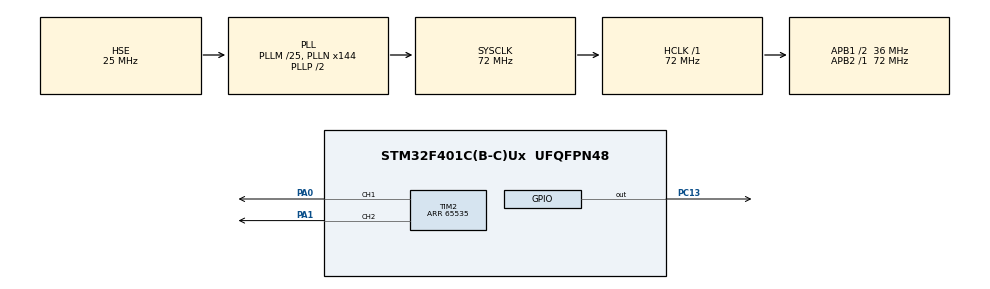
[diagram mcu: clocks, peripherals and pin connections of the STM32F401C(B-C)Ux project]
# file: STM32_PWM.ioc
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Mcu.Family=STM32F4
Mcu.Name=STM32F401C(B-C)Ux
Mcu.Package=UFQFPN48
NVIC.PriorityGroup=NVIC_PRIORITYGROUP_4
PA0-WKUP.Signal=S_TIM2_CH1_ETR
PA1.Signal=S_TIM2_CH2
PC13-ANTI_TAMP.Signal=GPIO_Output
PH0\ -\ OSC_IN.Mode=HSE-External-Oscillator
PH0\ -\ OSC_IN.Signal=RCC_OSC_IN
PH1\ -\ OSC_OUT.Mode=HSE-External-Oscillator
PH1\ -\ OSC_OUT.Signal=RCC_OSC_OUT
ProjectManager.HeapSize=0x200
ProjectManager.StackSize=0x400
ProjectManager.TargetToolchain=STM32CubeIDE
RCC.48MHZClocksFreq_Value=36000000
RCC.AHBFreq_Value=72000000
RCC.APB1CLKDivider=RCC_HCLK_DIV2
RCC.APB1Freq_Value=36000000
RCC.APB1TimFreq_Value=72000000
RCC.APB2Freq_Value=72000000
RCC.APB2TimFreq_Value=72000000
RCC.CortexFreq_Value=72000000
RCC.HCLKFreq_Value=72000000
RCC.HSE_VALUE=25000000
RCC.HSI_VALUE=16000000
RCC.LSE_VALUE=32768
RCC.PLLM=25
RCC.PLLN=144
RCC.PLLSourceVirtual=RCC_PLLSOURCE_HSE
RCC.SYSCLKFreq_VALUE=72000000
RCC.SYSCLKSource=RCC_SYSCLKSOURCE_PLLCLK
RCC.VCOOutputFreq_Value=144000000
SH.S_TIM2_CH1_ETR.0=TIM2_CH1,PWM Generation1 CH1
SH.S_TIM2_CH2.0=TIM2_CH2,PWM Generation2 CH2
TIM2.AutoReloadPreload=TIM_AUTORELOAD_PRELOAD_ENABLE
TIM2.Channel-PWM\ Generation1\ CH1=TIM_CHANNEL_1
TIM2.Channel-PWM\ Generation2\ CH2=TIM_CHANNEL_2
TIM2.Period=65535
VP_TIM2_VS_ClockSourceINT.Mode=Internal
board=custom

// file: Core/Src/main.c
/* USER CODE BEGIN Header */
/**
  ******************************************************************************
  * @file           : main.c
  * @brief          : Main program body
  ******************************************************************************
  * @attention
  *
  * Copyright (c) 2021 STMicroelectronics.
  * All rights reserved.
  *
  * This software is licensed under terms that can be found in the LICENSE file
  * in the root directory of this software component.
  * If no LICENSE file comes with this software, it is provided AS-IS.
  *
  ******************************************************************************
  */
/* USER CODE END Header */
#include "main.h"
#include "tim.h"
#include "gpio.h"

void SystemClock_Config(void);

int main(void)
{
  /* USER CODE BEGIN 1 */
	int32_t pwm_resolution = 65535;
	int32_t cycles = 500;
	int32_t pwm_increment = pwm_resolution/cycles;
	int32_t current_pwm = 0;
	int32_t cycle_duration = 2; // In milliseconds
	int32_t direction = 1;
	int32_t current_cycle = 0;
	int32_t pin_select = 1;
  /* USER CODE END 1 */

  /* MCU Configuration--------------------------------------------------------*/

  /* Reset of all peripherals, Initializes the Flash interface and the Systick. */
  HAL_Init();

  /* Configure the system clock */
  SystemClock_Config();

  /* Initialize all configured peripherals */
  MX_GPIO_Init();
  MX_TIM2_Init();
  /* USER CODE BEGIN 2 */
	GPIOC -> ODR |= GPIO_PIN_13;
  /* USER CODE END 2 */

  /* Infinite loop */
  /* USER CODE BEGIN WHILE */
  HAL_TIM_PWM_Start(&htim2, TIM_CHANNEL_1);
  HAL_TIM_PWM_Start(&htim2, TIM_CHANNEL_2);
  int32_t timer = HAL_GetTick();
	while (1)
	{
		if ((HAL_GetTick() - timer) > cycle_duration)
		{
			current_pwm += pwm_increment * direction;
			if (pin_select == 1)
				TIM2->CCR1 = current_pwm;
			else
				TIM2->CCR2 = current_pwm;

			current_cycle += direction;
			if (current_cycle >= cycles)
				direction *= -1; // reached half a cycle, flip direction
			else if (current_cycle <= 0)
			{
				direction *= -1; // reached end of a cycle, flip direction and pin
				pin_select *= -1;
				HAL_Delay(250);
			}

			timer = HAL_GetTick();
		}
	}
    /* USER CODE END WHILE */

}

void SystemClock_Config(void)
{
  RCC_OscInitTypeDef RCC_OscInitStruct = {0};
  RCC_ClkInitTypeDef RCC_ClkInitStruct = {0};

  /** Configure the main internal regulator output voltage
  */
  __HAL_RCC_PWR_CLK_ENABLE();
  __HAL_PWR_VOLTAGESCALING_CONFIG(PWR_REGULATOR_VOLTAGE_SCALE2);
  /** Initializes the RCC Oscillators according to the specified parameters
  * in the RCC_OscInitTypeDef structure.
  */
  RCC_OscInitStruct.OscillatorType = RCC_OSCILLATORTYPE_HSE;
  RCC_OscInitStruct.HSEState = RCC_HSE_ON;
  RCC_OscInitStruct.PLL.PLLState = RCC_PLL_ON;
  RCC_OscInitStruct.PLL.PLLSource = RCC_PLLSOURCE_HSE;
  RCC_OscInitStruct.PLL.PLLM = 25;
  RCC_OscInitStruct.PLL.PLLN = 144;
  RCC_OscInitStruct.PLL.PLLP = RCC_PLLP_DIV2;
  RCC_OscInitStruct.PLL.PLLQ = 4;
  if (HAL_RCC_OscConfig(&RCC_OscInitStruct) != HAL_OK)
  {
    Error_Handler();
  }
  /** Initializes the CPU, AHB and APB buses clocks
  */
  RCC_ClkInitStruct.ClockType = RCC_CLOCKTYPE_HCLK|RCC_CLOCKTYPE_SYSCLK
                              |RCC_CLOCKTYPE_PCLK1|RCC_CLOCKTYPE_PCLK2;
  RCC_ClkInitStruct.SYSCLKSource = RCC_SYSCLKSOURCE_PLLCLK;
  RCC_ClkInitStruct.AHBCLKDivider = RCC_SYSCLK_DIV1;
  RCC_ClkInitStruct.APB1CLKDivider = RCC_HCLK_DIV2;
  RCC_ClkInitStruct.APB2CLKDivider = RCC_HCLK_DIV1;

  if (HAL_RCC_ClockConfig(&RCC_ClkInitStruct, FLASH_LATENCY_2) != HAL_OK)
  {
    Error_Handler();
  }
}

void Error_Handler(void)
{
  __disable_irq();
  while (1)
  {
  }
}
